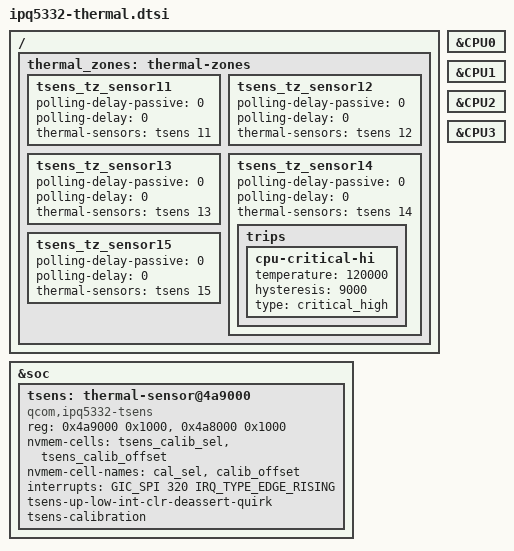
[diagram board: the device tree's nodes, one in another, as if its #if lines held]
/*
 * Copyright (c) 2019-2021, The Linux Foundation. All rights reserved.
 *
 * Copyright (c) 2022 Qualcomm Innovation Center, Inc. All rights reserved.
 *
 * Permission to use, copy, modify, and/or distribute this software for any
 * purpose with or without fee is hereby granted, provided that the above
 * copyright notice and this permission notice appear in all copies.
 *
 * THE SOFTWARE IS PROVIDED "AS IS" AND THE AUTHOR DISCLAIMS ALL WARRANTIES
 * WITH REGARD TO THIS SOFTWARE INCLUDING ALL IMPLIED WARRANTIES OF
 * MERCHANTABILITY AND FITNESS. IN NO EVENT SHALL THE AUTHOR BE LIABLE FOR
 * ANY SPECIAL, DIRECT, INDIRECT, OR CONSEQUENTIAL DAMAGES OR ANY DAMAGES
 * WHATSOEVER RESULTING FROM LOSS OF USE, DATA OR PROFITS, WHETHER IN AN
 * ACTION OF CONTRACT, NEGLIGENCE OR OTHER TORTIOUS ACTION, ARISING OUT OF
 * OR IN CONNECTION WITH THE USE OR PERFORMANCE OF THIS SOFTWARE.
 */

/ {
	thermal_zones: thermal-zones {
		tsens_tz_sensor11 {
			polling-delay-passive = <0>;
			polling-delay = <0>;
			thermal-sensors = <&tsens 11>;

			trips {
				cpu-critical-hi {
					temperature = <125000>;
					hysteresis = <2>;
					type = "critical_high";
				};

				cpu-config-hi {
					temperature = <105000>;
					hysteresis = <2>;
					type = "configurable_hi";
				};

				cpu-config-lo {
					temperature = <95000>;
					hysteresis = <2>;
					type = "configurable_lo";
				};

				cpu-critical-low {
					temperature = <0>;
					hysteresis = <2>;
					type = "critical_low";
				};
			};
		};

		tsens_tz_sensor12 {
			polling-delay-passive = <0>;
			polling-delay = <0>;
			thermal-sensors = <&tsens 12>;

			trips {
				cpu-critical-hi {
					temperature = <125000>;
					hysteresis = <2>;
					type = "critical_high";
				};

				cpu-config-hi {
					temperature = <105000>;
					hysteresis = <2>;
					type = "configurable_hi";
				};

				cpu-config-lo {
					temperature = <95000>;
					hysteresis = <2>;
					type = "configurable_lo";
				};

				cpu-critical-low {
					temperature = <0>;
					hysteresis = <2>;
					type = "critical_low";
				};
			};
		};

		tsens_tz_sensor13 {
			polling-delay-passive = <0>;
			polling-delay = <0>;
			thermal-sensors = <&tsens 13>;

			trips {
				cpu-critical-hi {
					temperature = <125000>;
					hysteresis = <2>;
					type = "critical_high";
				};

				cpu-config-hi {
					temperature = <105000>;
					hysteresis = <2>;
					type = "configurable_hi";
				};

				cpu-config-lo {
					temperature = <95000>;
					hysteresis = <2>;
					type = "configurable_lo";
				};

				cpu-critical-low {
					temperature = <0>;
					hysteresis = <2>;
					type = "critical_low";
				};
			};
		};

		tsens_tz_sensor14 {
			polling-delay-passive = <0>;
			polling-delay = <0>;
			thermal-sensors = <&tsens 14>;

			trips {
				cpu-critical-hi {
					temperature = <125000>;
					hysteresis = <2>;
					type = "critical_high";
				};

				cpu-config-hi {
					temperature = <105000>;
					hysteresis = <2>;
					type = "configurable_hi";
				};

				cpu-config-lo {
					temperature = <95000>;
					hysteresis = <2>;
					type = "configurable_lo";
				};

				cpu-critical-low {
					temperature = <0>;
					hysteresis = <2>;
					type = "critical_low";
				};
			};
		};

		tsens_tz_sensor15 {
			polling-delay-passive = <0>;
			polling-delay = <0>;
			thermal-sensors = <&tsens 15>;

			trips {
				cpu-critical-hi {
					temperature = <125000>;
					hysteresis = <2>;
					type = "critical_high";
				};

				cpu-config-hi {
					temperature = <105000>;
					hysteresis = <2>;
					type = "configurable_hi";
				};

				cpu-config-lo {
					temperature = <95000>;
					hysteresis = <2>;
					type = "configurable_lo";
				};

				cpu-critical-low {
					temperature = <0>;
					hysteresis = <2>;
					type = "critical_low";
				};
			};
		};
	};
};

&soc {
	tsens: thermal-sensor@4a9000 {
		compatible = "qcom,ipq5332-tsens";
		reg = <0x4a9000 0x1000>, /* TM */
		      <0x4a8000 0x1000>; /* SROT */
		nvmem-cells = <&tsens_calib_sel>, <&tsens_calib_offset>;
		nvmem-cell-names = "cal_sel", "calib_offset";
		interrupts = <GIC_SPI 320 IRQ_TYPE_EDGE_RISING>;
		#thermal-sensor-cells = <1>;
		tsens-up-low-int-clr-deassert-quirk;
		tsens-calibration;
		status = "ok";
	};
};

/* If CPUFreq cooling is enabled */
#if defined(__CPU_THERMAL__)

&thermal_zones {
	tsens_tz_sensor11 {
		/delete-node/ trips;
	};

	tsens_tz_sensor12 {
		/delete-node/ trips;
	};

	tsens_tz_sensor13 {
		/delete-node/ trips;
	};

	tsens_tz_sensor14 {
		/delete-node/ trips;

		/* Trips with CPUFreq cooling maps */
		trips {
			cpu-critical-hi {
				temperature = <120000>;
				hysteresis = <9000>;
				type = "critical_high";
			};
		};
	};

	tsens_tz_sensor15 {
		/delete-node/ trips;
	};
};

&CPU0 {
	#cooling-cells = <2>;
};

&CPU1 {
	#cooling-cells = <2>;
};

&CPU2 {
	#cooling-cells = <2>;
};

&CPU3 {
	#cooling-cells = <2>;
};
#endif
